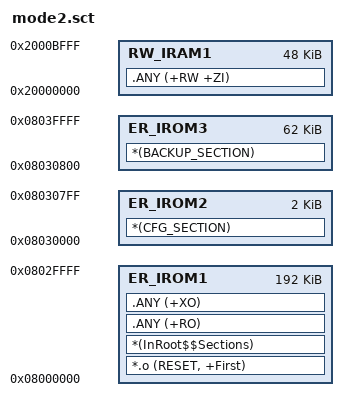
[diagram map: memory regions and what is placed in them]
; *************************************************************
; *** Scatter-Loading Description File generated by uVision ***
; *************************************************************

LR_IROM1 0x08000000 0x00030000  {    ; load region size_region
  ER_IROM1 0x08000000 0x00030000  {  ; load address = execution address
   *.o (RESET, +First)
   *(InRoot$$Sections)
   .ANY (+RO)
   .ANY (+XO)
  }
  RW_IRAM1 0x20000000 0x0000C000  {  ; RW data
   .ANY (+RW +ZI)
  }
}

LR_IROM2 0x08030000 0x00000800  {    ; load region size_region
  ER_IROM2 0x08030000 0x00000800  {  ; load address = execution address
    *(CFG_SECTION)
  }
}

LR_IROM3 0x08030800 0x0000F800  {    ; load region size_region
  ER_IROM3 0x08030800 0x0000F800  {  ; load address = execution address
    *(BACKUP_SECTION)
  }
}
